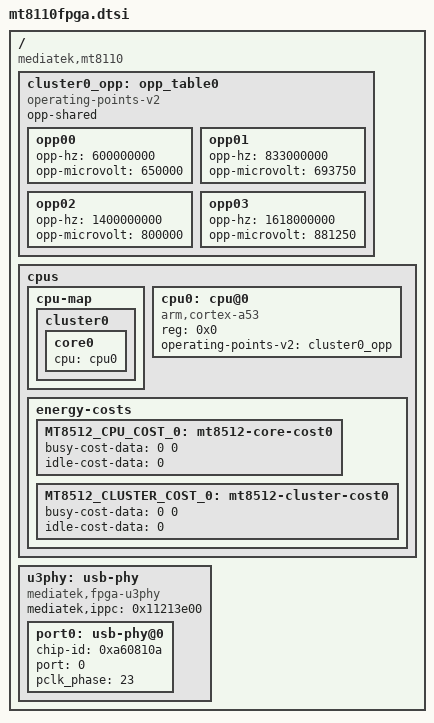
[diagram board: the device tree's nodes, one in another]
/*
 * Copyright (c) 2019 MediaTek Inc.
 *
 * SPDX-License-Identifier: (GPL-2.0 OR MIT)
 */

#include "mt8512.dtsi"

/ {
	compatible = "mediatek,mt8110";

	cluster0_opp: opp_table0 {
		compatible = "operating-points-v2";
		opp-shared;
		opp00 {
			opp-hz = /bits/ 64 <600000000>;
			opp-microvolt = <650000>;
		};
		opp01 {
			opp-hz = /bits/ 64 <833000000>;
			opp-microvolt = <693750>;
		};
		opp02 {
			opp-hz = /bits/ 64 <1400000000>;
			opp-microvolt = <800000>;
		};
		opp03 {
			opp-hz = /bits/ 64 <1618000000>;
			opp-microvolt = <881250>;
		};
	};

	cpus {
		#address-cells = <1>;
		#size-cells = <0>;

		cpu-map {
			cluster0 {
				core0 {
					cpu = <&cpu0>;
				};
			};
		};

		cpu0: cpu@0 {
			device_type = "cpu";
			compatible = "arm,cortex-a53";
			reg = <0x0>;
			operating-points-v2 = <&cluster0_opp>;
		};

		energy-costs {
			MT8512_CPU_COST_0: mt8512-core-cost0 {
				busy-cost-data = <0 0>;
				idle-cost-data = <0>;
			};
			MT8512_CLUSTER_COST_0: mt8512-cluster-cost0 {
				busy-cost-data = <0 0>;
				idle-cost-data = <0>;
			};
		};
	};

	u3phy: usb-phy {
		compatible = "mediatek,fpga-u3phy";
		mediatek,ippc = <0x11213e00>;
		#address-cells = <2>;
		#size-cells = <2>;
		port0: usb-phy@0 {
			chip-id= <0xa60810a>;
			port = <0>;
			pclk_phase = <23>;
			#phy-cells = <1>;
		};
	};
};
